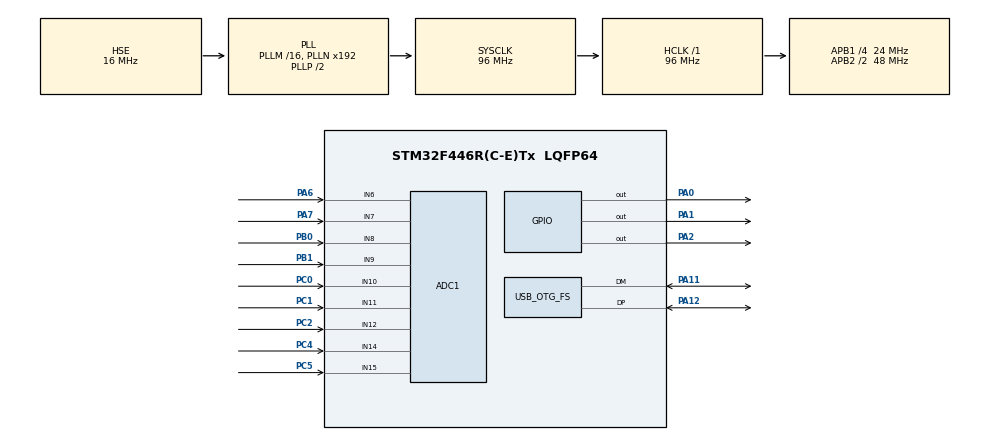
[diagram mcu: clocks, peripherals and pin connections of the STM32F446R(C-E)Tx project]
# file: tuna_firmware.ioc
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ADC1.Channel-1\#ChannelRegularConversion=ADC_CHANNEL_10
ADC1.NbrOfConversionFlag=1
ADC1.Rank-1\#ChannelRegularConversion=1
ADC1.SamplingTime-1\#ChannelRegularConversion=ADC_SAMPLETIME_28CYCLES
ADC1.master=1
Mcu.Family=STM32F4
Mcu.Name=STM32F446R(C-E)Tx
Mcu.Package=LQFP64
NVIC.PriorityGroup=NVIC_PRIORITYGROUP_4
NVIC.TIM2_IRQn=true\:0\:0\:false\:false\:true\:true\:true\:true
PA0-WKUP.Signal=GPIO_Output
PA1.Signal=GPIO_Output
PA11.Mode=Device_Only
PA11.Signal=USB_OTG_FS_DM
PA12.Mode=Device_Only
PA12.Signal=USB_OTG_FS_DP
PA13.Mode=Trace_Asynchronous_SW
PA13.Signal=SYS_JTMS-SWDIO
PA14.Mode=Trace_Asynchronous_SW
PA14.Signal=SYS_JTCK-SWCLK
PA2.Signal=GPIO_Output
PA6.Signal=ADCx_IN6
PA7.Signal=ADCx_IN7
PB0.Signal=ADCx_IN8
PB1.Signal=ADCx_IN9
PB3.Mode=Trace_Asynchronous_SW
PB3.Signal=SYS_JTDO-SWO
PC0.Signal=ADCx_IN10
PC1.Signal=ADCx_IN11
PC2.Signal=ADCx_IN12
PC4.Signal=ADCx_IN14
PC5.Signal=ADCx_IN15
PH0-OSC_IN.Mode=HSE-External-Oscillator
PH0-OSC_IN.Signal=RCC_OSC_IN
PH1-OSC_OUT.Mode=HSE-External-Oscillator
PH1-OSC_OUT.Signal=RCC_OSC_OUT
ProjectManager.HeapSize=0x200
ProjectManager.StackSize=0x400
ProjectManager.TargetToolchain=CMake
RCC.AHBFreq_Value=96000000
RCC.APB1CLKDivider=RCC_HCLK_DIV4
RCC.APB1Freq_Value=24000000
RCC.APB1TimFreq_Value=48000000
RCC.APB2CLKDivider=RCC_HCLK_DIV2
RCC.APB2Freq_Value=48000000
RCC.APB2TimFreq_Value=96000000
RCC.CortexFreq_Value=96000000
RCC.HCLKFreq_Value=96000000
RCC.HSE_VALUE=16000000
RCC.PLLQ=4
RCC.SYSCLKFreq_VALUE=96000000
RCC.SYSCLKSource=RCC_SYSCLKSOURCE_PLLCLK
RCC.USBFreq_Value=48000000
RCC.VCOOutputFreq_Value=192000000
SH.ADCx_IN10.0=ADC1_IN10,IN10
SH.ADCx_IN11.0=ADC1_IN11,IN11
SH.ADCx_IN12.0=ADC1_IN12,IN12
SH.ADCx_IN14.0=ADC1_IN14,IN14
SH.ADCx_IN15.0=ADC1_IN15,IN15
SH.ADCx_IN6.0=ADC1_IN6,IN6
SH.ADCx_IN7.0=ADC1_IN7,IN7
SH.ADCx_IN8.0=ADC1_IN8,IN8
SH.ADCx_IN9.0=ADC1_IN9,IN9
TIM2.AutoReloadPreload=TIM_AUTORELOAD_PRELOAD_ENABLE
TIM2.Period=249
TIM2.Prescaler=95
USB_OTG_FS.VirtualMode=Device_Only
VP_TIM2_VS_ClockSourceINT.Mode=Internal
VP_TIM2_VS_ClockSourceITR.Mode=TriggerSource_ITR1
board=custom

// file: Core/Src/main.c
/* USER CODE BEGIN Header */
/**
  ******************************************************************************
  * @file           : main.c
  * @brief          : Main program body
  ******************************************************************************
  * @attention
  *
  * Copyright (c) 2026 STMicroelectronics.
  * All rights reserved.
  *
  * This software is licensed under terms that can be found in the LICENSE file
  * in the root directory of this software component.
  * If no LICENSE file comes with this software, it is provided AS-IS.
  *
  ******************************************************************************
  */
/* USER CODE END Header */
#include "main.h"

/* USER CODE BEGIN Includes */
#include "keyboard.h"
#include "usb.h"
/* USER CODE END Includes */

ADC_HandleTypeDef hadc1;

TIM_HandleTypeDef htim2;

PCD_HandleTypeDef hpcd_USB_OTG_FS;

void SystemClock_Config(void);
static void MX_GPIO_Init(void);
static void MX_ADC1_Init(void);
static void MX_USB_OTG_FS_PCD_Init(void);
static void MX_TIM2_Init(void);

int main(void)
{

  /* MCU Configuration--------------------------------------------------------*/

  /* Reset of all peripherals, Initializes the Flash interface and the Systick. */
  HAL_Init();

  /* Configure the system clock */
  SystemClock_Config();

  /* Initialize all configured peripherals */
  MX_GPIO_Init();
  MX_ADC1_Init();
  MX_USB_OTG_FS_PCD_Init();
  MX_TIM2_Init();
  /* USER CODE BEGIN 2 */
  keyboard_init();
  /* USER CODE END 2 */

  /* Infinite loop */
  while (1)
  {

    /* USER CODE BEGIN 3 */
    usb_task();      /* pump TinyUSB every iteration — must outpace the 4kHz scan */
    keyboard_task(); /* runs one scan per 250µs tick, else returns immediately */
  }
  /* USER CODE END 3 */
}

void SystemClock_Config(void)
{
  RCC_OscInitTypeDef RCC_OscInitStruct = {0};
  RCC_ClkInitTypeDef RCC_ClkInitStruct = {0};

  /** Configure the main internal regulator output voltage
  */
  __HAL_RCC_PWR_CLK_ENABLE();
  __HAL_PWR_VOLTAGESCALING_CONFIG(PWR_REGULATOR_VOLTAGE_SCALE3);

  /** Initializes the RCC Oscillators according to the specified parameters
  * in the RCC_OscInitTypeDef structure.
  */
  RCC_OscInitStruct.OscillatorType = RCC_OSCILLATORTYPE_HSE;
  RCC_OscInitStruct.HSEState = RCC_HSE_ON;
  RCC_OscInitStruct.PLL.PLLState = RCC_PLL_ON;
  RCC_OscInitStruct.PLL.PLLSource = RCC_PLLSOURCE_HSE;
  RCC_OscInitStruct.PLL.PLLM = 16;
  RCC_OscInitStruct.PLL.PLLN = 192;
  RCC_OscInitStruct.PLL.PLLP = RCC_PLLP_DIV2;
  RCC_OscInitStruct.PLL.PLLQ = 4;
  RCC_OscInitStruct.PLL.PLLR = 2;
  if (HAL_RCC_OscConfig(&RCC_OscInitStruct) != HAL_OK)
  {
    Error_Handler();
  }

  /** Initializes the CPU, AHB and APB buses clocks
  */
  RCC_ClkInitStruct.ClockType = RCC_CLOCKTYPE_HCLK|RCC_CLOCKTYPE_SYSCLK
                              |RCC_CLOCKTYPE_PCLK1|RCC_CLOCKTYPE_PCLK2;
  RCC_ClkInitStruct.SYSCLKSource = RCC_SYSCLKSOURCE_PLLCLK;
  RCC_ClkInitStruct.AHBCLKDivider = RCC_SYSCLK_DIV1;
  RCC_ClkInitStruct.APB1CLKDivider = RCC_HCLK_DIV4;
  RCC_ClkInitStruct.APB2CLKDivider = RCC_HCLK_DIV2;

  if (HAL_RCC_ClockConfig(&RCC_ClkInitStruct, FLASH_LATENCY_3) != HAL_OK)
  {
    Error_Handler();
  }
}

static void MX_ADC1_Init(void)
{

  ADC_ChannelConfTypeDef sConfig = {0};

  /** Configure the global features of the ADC (Clock, Resolution, Data Alignment and number of conversion)
  */
  hadc1.Instance = ADC1;
  hadc1.Init.ClockPrescaler = ADC_CLOCK_SYNC_PCLK_DIV2;
  hadc1.Init.Resolution = ADC_RESOLUTION_12B;
  hadc1.Init.ScanConvMode = DISABLE;
  hadc1.Init.ContinuousConvMode = DISABLE;
  hadc1.Init.DiscontinuousConvMode = DISABLE;
  hadc1.Init.ExternalTrigConvEdge = ADC_EXTERNALTRIGCONVEDGE_NONE;
  hadc1.Init.ExternalTrigConv = ADC_SOFTWARE_START;
  hadc1.Init.DataAlign = ADC_DATAALIGN_RIGHT;
  hadc1.Init.NbrOfConversion = 1;
  hadc1.Init.DMAContinuousRequests = DISABLE;
  hadc1.Init.EOCSelection = ADC_EOC_SINGLE_CONV;
  if (HAL_ADC_Init(&hadc1) != HAL_OK)
  {
    Error_Handler();
  }

  /** Configure for the selected ADC regular channel its corresponding rank in the sequencer and its sample time.
  */
  sConfig.Channel = ADC_CHANNEL_10;
  sConfig.Rank = 1;
  sConfig.SamplingTime = ADC_SAMPLETIME_28CYCLES;
  if (HAL_ADC_ConfigChannel(&hadc1, &sConfig) != HAL_OK)
  {
    Error_Handler();
  }

}

static void MX_TIM2_Init(void)
{

  TIM_ClockConfigTypeDef sClockSourceConfig = {0};
  TIM_SlaveConfigTypeDef sSlaveConfig = {0};
  TIM_MasterConfigTypeDef sMasterConfig = {0};

  htim2.Instance = TIM2;
  htim2.Init.Prescaler = 95;
  htim2.Init.CounterMode = TIM_COUNTERMODE_UP;
  htim2.Init.Period = 249;
  htim2.Init.ClockDivision = TIM_CLOCKDIVISION_DIV1;
  htim2.Init.AutoReloadPreload = TIM_AUTORELOAD_PRELOAD_ENABLE;
  if (HAL_TIM_Base_Init(&htim2) != HAL_OK)
  {
    Error_Handler();
  }
  sClockSourceConfig.ClockSource = TIM_CLOCKSOURCE_INTERNAL;
  if (HAL_TIM_ConfigClockSource(&htim2, &sClockSourceConfig) != HAL_OK)
  {
    Error_Handler();
  }
  sSlaveConfig.SlaveMode = TIM_SLAVEMODE_DISABLE;
  sSlaveConfig.InputTrigger = TIM_TS_ITR1;
  if (HAL_TIM_SlaveConfigSynchro(&htim2, &sSlaveConfig) != HAL_OK)
  {
    Error_Handler();
  }
  sMasterConfig.MasterOutputTrigger = TIM_TRGO_RESET;
  sMasterConfig.MasterSlaveMode = TIM_MASTERSLAVEMODE_DISABLE;
  if (HAL_TIMEx_MasterConfigSynchronization(&htim2, &sMasterConfig) != HAL_OK)
  {
    Error_Handler();
  }

}

static void MX_USB_OTG_FS_PCD_Init(void)
{

  hpcd_USB_OTG_FS.Instance = USB_OTG_FS;
  hpcd_USB_OTG_FS.Init.dev_endpoints = 6;
  hpcd_USB_OTG_FS.Init.speed = PCD_SPEED_FULL;
  hpcd_USB_OTG_FS.Init.dma_enable = DISABLE;
  hpcd_USB_OTG_FS.Init.phy_itface = PCD_PHY_EMBEDDED;
  hpcd_USB_OTG_FS.Init.Sof_enable = DISABLE;
  hpcd_USB_OTG_FS.Init.low_power_enable = DISABLE;
  hpcd_USB_OTG_FS.Init.lpm_enable = DISABLE;
  hpcd_USB_OTG_FS.Init.vbus_sensing_enable = DISABLE;
  hpcd_USB_OTG_FS.Init.use_dedicated_ep1 = DISABLE;
  if (HAL_PCD_Init(&hpcd_USB_OTG_FS) != HAL_OK)
  {
    Error_Handler();
  }

}

static void MX_GPIO_Init(void)
{
  GPIO_InitTypeDef GPIO_InitStruct = {0};

  /* GPIO Ports Clock Enable */
  __HAL_RCC_GPIOH_CLK_ENABLE();
  __HAL_RCC_GPIOC_CLK_ENABLE();
  __HAL_RCC_GPIOA_CLK_ENABLE();
  __HAL_RCC_GPIOB_CLK_ENABLE();

  /*Configure GPIO pin Output Level */
  HAL_GPIO_WritePin(GPIOA, GPIO_PIN_0|GPIO_PIN_1|GPIO_PIN_2, GPIO_PIN_RESET);

  /*Configure GPIO pins : PA0 PA1 PA2 */
  GPIO_InitStruct.Pin = GPIO_PIN_0|GPIO_PIN_1|GPIO_PIN_2;
  GPIO_InitStruct.Mode = GPIO_MODE_OUTPUT_PP;
  GPIO_InitStruct.Pull = GPIO_NOPULL;
  GPIO_InitStruct.Speed = GPIO_SPEED_FREQ_LOW;
  HAL_GPIO_Init(GPIOA, &GPIO_InitStruct);

}

void Error_Handler(void)
{
  __disable_irq();
  while (1)
  {
  }
}
